# va416xx register map
Vendor: VORAGO TECHNOLOGIES; Series: M4; File version: 1.3
CPU: CM4 r0p1, little endian, no MPU, FPU, 3 interrupt priority bits
Registers are 32-bit, read-write, reset 0x0 unless marked. A register's access mark holds for its fields unless they carry their own. Offsets are from the block's base; [hi:lo] are bit positions.

## ADC — Analog to Digital Converter Peripheral
Base 0x40022000
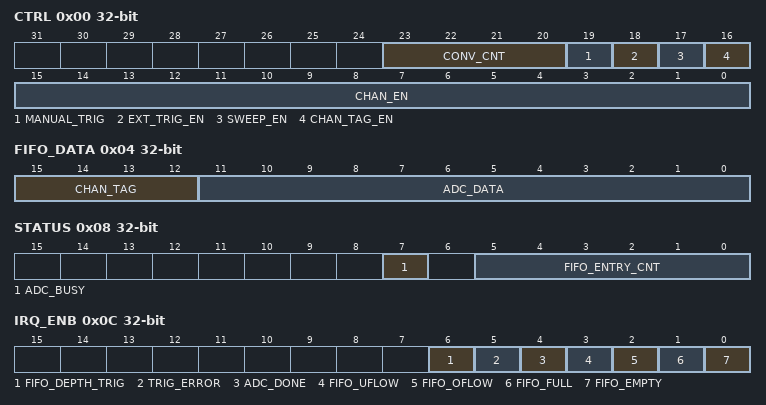
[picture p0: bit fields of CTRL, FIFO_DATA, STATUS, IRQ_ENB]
0x00 CTRL — Control Register
  [23:20] CONV_CNT — Conversion count describes the number of conversions to be applied for triggers/sweeps. (N+1 conversions)
  [19] MANUAL_TRIG — Starts analog acquisition
  [18] EXT_TRIG_EN — Allows the external trigger to start analog acquisition
  [17] SWEEP_EN — ADC data acquisition for all enabled channel
  [16] CHAN_TAG_EN — Enables the channel tag to be saved with the ADC data
  [15:0] CHAN_EN — Enables the channel for data collection
0x04 FIFO_DATA ro
  [15:12] CHAN_TAG — If enabled, this will include the number of the channel corresponding to the measurement
  [11:0] ADC_DATA — ADC acquisition data from the FIFO
0x08 STATUS ro
  [7] ADC_BUSY — Indicates an ADC data acquisition is in process
  [5:0] FIFO_ENTRY_CNT — Indicates the number of entries in the FIFO
0x0C IRQ_ENB — Interrupt Enable
  [6] FIFO_DEPTH_TRIG — Enables the interrupt for the FIFO entry count meets or exceeds the trigger level
  [5] TRIG_ERROR — Enables the interrupt for a trigger error
  [4] ADC_DONE — Enables the interrupt for an ADC data acquisition completion
  [3] FIFO_UFLOW — Enables the interrupt for a FIFO underflow
  [2] FIFO_OFLOW — Enables the interrupt for a FIFO overflow
  [1] FIFO_FULL — Enables the interrupt for FIFO full
  [0] FIFO_EMPTY — Enables the interrupt for FIFO empty
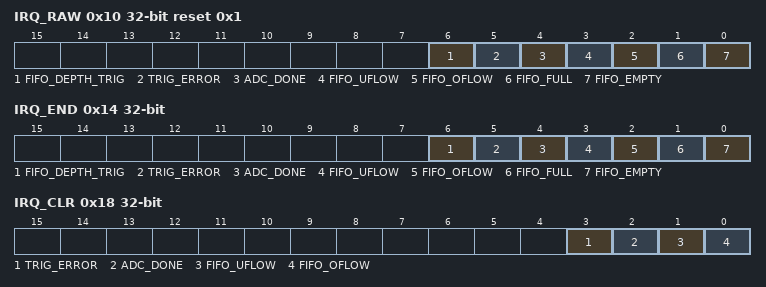
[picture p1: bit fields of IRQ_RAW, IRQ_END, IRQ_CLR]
0x10 IRQ_RAW ro reset 0x1 — Raw Interrupt Status
  [6] FIFO_DEPTH_TRIG — Indicates the interrupt for the FIFO entry count meets or exceeds the trigger level
  [5] TRIG_ERROR — Indicates a manual or external trigger occurred when the ADC was BUSY doing a conversion
  [4] ADC_DONE — Indicates that a ADC conversion is done
  [3] FIFO_UFLOW — Indicates data was unavailable when a new trigger for ADC update is received
  [2] FIFO_OFLOW — Indicates a FIFO overflow occurred (FIFO was full when new data was written)
  [1] FIFO_FULL — Indicates the FIFO is full
  [0] FIFO_EMPTY — Indicates the FIFO is empty
0x14 IRQ_END ro — Enabled Interrupt Status
  [6] FIFO_DEPTH_TRIG — Indicates the interrupt for the FIFO entry count meets or exceeds the trigger level
  [5] TRIG_ERROR — Indicates a manual or external trigger occurred when the ADC was BUSY doing a conversion and the interrupt is enabled
  [4] ADC_DONE — Indicates that a ADC conversion is done and the interrupt is enabled
  [3] FIFO_UFLOW — Indicates a FIFO underflow occurred and the interrupt is enabled
  [2] FIFO_OFLOW — Indicates a FIFO overflow occurred and the interrupt is enabled
  [1] FIFO_FULL — Indicates the FIFO is full and the interrupt is enabled
  [0] FIFO_EMPTY — Indicates the FIFO is empty and the interrupt is enabled
0x18 IRQ_CLR wo — Clear Interrupt
  [3] TRIG_ERROR — Clears the trigger error interrupt status. Always reads 0
  [2] ADC_DONE — Clears the ADC done interrupt status. Always reads 0
  [1] FIFO_UFLOW — Clears the FIFO underflow interrupt status. Always reads 0
  [0] FIFO_OFLOW — Clears the FIFO overflow interrupt status. Always reads 0
0x1C RXFIFOIRQTRG reset 0x10 — Receive FIFO Interrupt Trigger Value
  [4:0] LEVEL — Sets the FIFO_ENTRY_CNT value that asserts the FIFO_DEPTH_TRIG interrupt
0x20 FIFO_CLR — FIFO Clear
  [0] FIFO_CLR wo — Clears the ADC FIFO. Always reads 0
0xFFC PERID ro reset 0x1907E9 — Peripheral ID Register

## DAC0 — Digital to Analog Converter Peripheral
Base 0x40023000
Same registers: DAC1 0x40023800
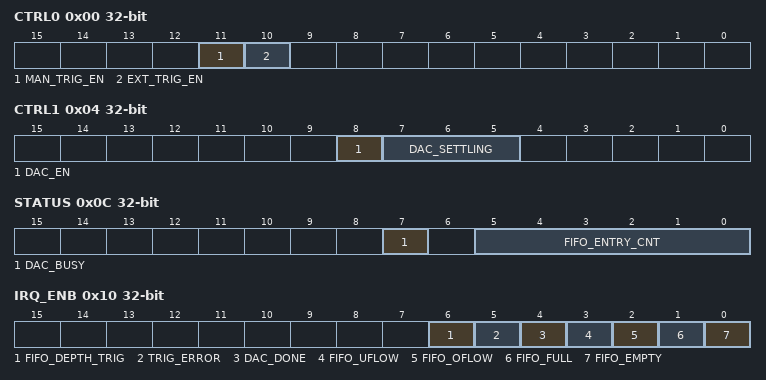
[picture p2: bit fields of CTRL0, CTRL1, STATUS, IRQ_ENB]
0x00 CTRL0 — Control Register 0
  [11] MAN_TRIG_EN — Enables manual trigger
  [10] EXT_TRIG_EN — Enables external trigger
0x04 CTRL1 — Control Register 1
  [8] DAC_EN — Enables the DAC analog block
  [7:5] DAC_SETTLING — Sets the the amount of time in microseconds the control FSM waits for the DAC settling time
0x08 FIFO_DATA
  [11:0] DATA wo — Data for FIFO write
0x0C STATUS ro
  [7] DAC_BUSY — Indicates a DAC data acquisition is in process
  [5:0] FIFO_ENTRY_CNT — Indicates the number of entries in the FIFO
0x10 IRQ_ENB — Interrupt Enable
  [6] FIFO_DEPTH_TRIG — Enables the interrupt for the FIFO entry count is less than or equal to the trigger level
  [5] TRIG_ERROR — Enables the interrupt for a trigger error
  [4] DAC_DONE — Enables the interrupt for a DAC data acquisition completion
  [3] FIFO_UFLOW — Enables the interrupt for a FIFO underflow
  [2] FIFO_OFLOW — Enables the interrupt for a FIFO overflow
  [1] FIFO_FULL — Enables the interrupt for FIFO full
  [0] FIFO_EMPTY — Enables the interrupt for FIFO empty
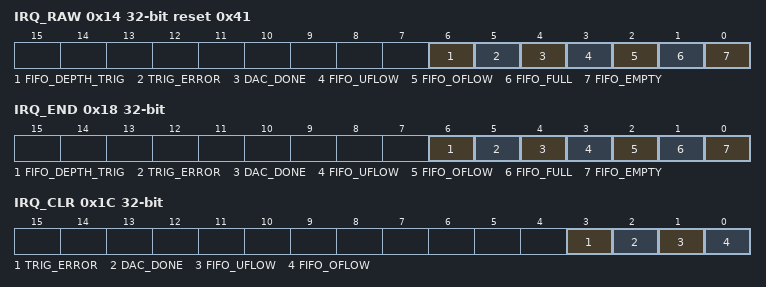
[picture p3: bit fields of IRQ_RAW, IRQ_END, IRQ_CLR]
0x14 IRQ_RAW ro reset 0x41 — Raw Interrupt Status
  [6] FIFO_DEPTH_TRIG — Indicates the FIFO entry count is less than or equal to the trigger level
  [5] TRIG_ERROR — Indicates a manual or external trigger occurred when the DAC was BUSY doing a conversion
  [4] DAC_DONE — Indicates that a DAC conversion is done
  [3] FIFO_UFLOW — Indicates data was unavailable when a new trigger for DAC update is received
  [2] FIFO_OFLOW — Indicates a FIFO overflow occurred (FIFO was full when new data was written)
  [1] FIFO_FULL — Indicates the FIFO is full
  [0] FIFO_EMPTY — Indicates the FIFO is empty
0x18 IRQ_END ro — Enabled Interrupt Status
  [6] FIFO_DEPTH_TRIG — Indicates the FIFO entry count is less than or equal to the trigger level and the interrupt is enabled
  [5] TRIG_ERROR — Indicates a manual or external trigger occurred when the DAC was BUSY doing a conversion and the interrupt is enabled
  [4] DAC_DONE — Indicates that a DAC conversion is done and the interrupt is enabled
  [3] FIFO_UFLOW — Indicates a FIFO underflow occurred and the interrupt is enabled
  [2] FIFO_OFLOW — Indicates a FIFO overflow occurred and the interrupt is enabled
  [1] FIFO_FULL — Indicates the FIFO is full and the interrupt is enabled
  [0] FIFO_EMPTY — Indicates the FIFO is empty and the interrupt is enabled
0x1C IRQ_CLR wo — Clear Interrupt
  [3] TRIG_ERROR — Clears the trigger error interrupt status. Always reads 0
  [2] DAC_DONE — Clears the DAC done interrupt status. Always reads 0
  [1] FIFO_UFLOW — Clears the FIFO underflow interrupt status. Always reads 0
  [0] FIFO_OFLOW — Clears the FIFO overflow interrupt status. Always reads 0
0x20 TXFIFOIRQTRG reset 0x10 — Receive FIFO Interrupt Trigger Value
  [4:0] LEVEL — Sets the FIFO_ENTRY_CNT value that asserts the FIFO_DEPTH_TRIG interrupt
0x24 FIFO_CLR — FIFO Clear
  [0] FIFO_CLR wo — Clears the DAC FIFO. Always reads 0
0x7FC PERID ro reset 0x2007E9 — Peripheral ID Register
